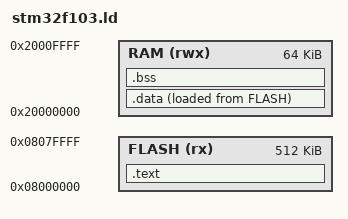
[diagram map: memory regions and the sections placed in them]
/* STM32F103 512KB flash / 64KB RAM linker script */

ENTRY(reset_handler)

MEMORY
{
    FLASH (rx)  : ORIGIN = 0x08000000, LENGTH = 512K
    RAM   (rwx) : ORIGIN = 0x20000000, LENGTH = 64K
}

/* Initial stack pointer at top of RAM (symbol name expected by libopencm3) */
_stack = ORIGIN(RAM) + LENGTH(RAM);

SECTIONS
{
    .text :
    {
        KEEP(*(.vectors))
        *(.text*)
        *(.rodata*)
        . = ALIGN(4);
        __preinit_array_start = .;
        KEEP(*(.preinit_array))
        __preinit_array_end = .;
        __init_array_start = .;
        KEEP(*(SORT(.init_array.*)))
        KEEP(*(.init_array))
        __init_array_end = .;
        __fini_array_start = .;
        KEEP(*(SORT(.fini_array.*)))
        KEEP(*(.fini_array))
        __fini_array_end = .;
    } > FLASH

    _data_loadaddr = LOADADDR(.data);

    .data :
    {
        _data = .;
        *(.data*)
        _edata = .;
    } > RAM AT > FLASH

    .bss :
    {
        _bss = .;
        *(.bss*)
        *(COMMON)
        _ebss = .;
    } > RAM

    . = ALIGN(8);
    _end = .;
}
